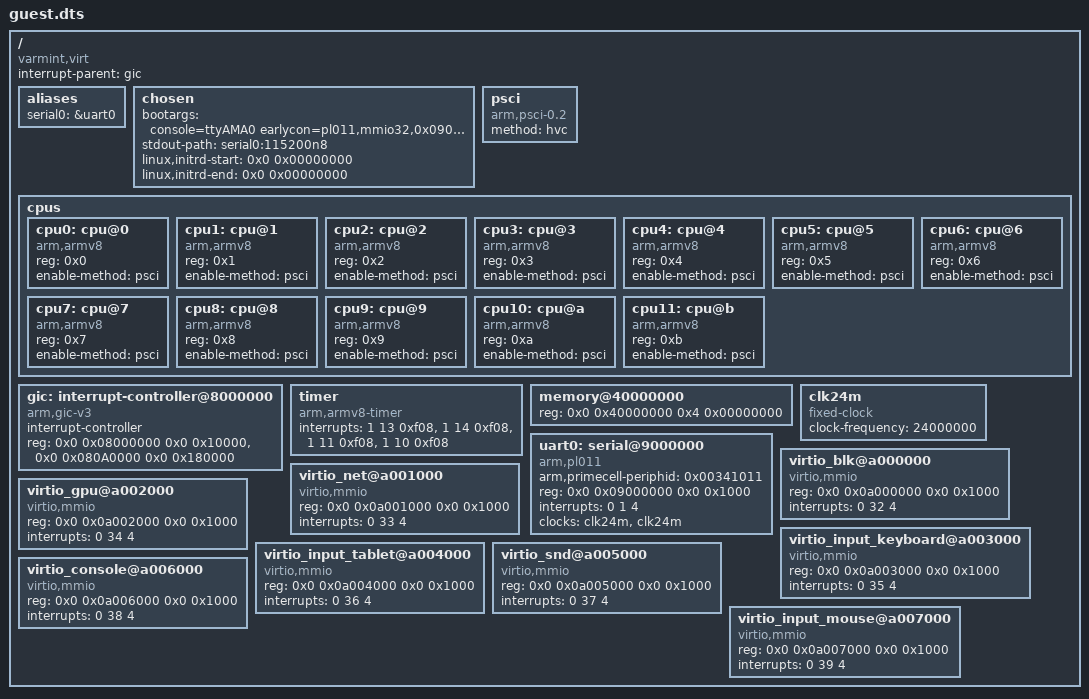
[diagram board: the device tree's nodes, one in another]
/dts-v1/;

/ {
	compatible = "varmint,virt";
	#address-cells = <2>;
	#size-cells = <2>;
	interrupt-parent = <&gic>;

	aliases {
		serial0 = &uart0;
	};

	chosen {
		bootargs = "console=ttyAMA0 earlycon=pl011,mmio32,0x09000000 root=/dev/vda3 rw";
		stdout-path = "serial0:115200n8";

		linux,initrd-start = <0x0 0x00000000>; // patched by scripts/build-dtb.sh
		linux,initrd-end = <0x0 0x00000000>; // patched by scripts/build-dtb.sh
	};

	psci {
		compatible = "arm,psci-0.2";
		method = "hvc";
	};

	cpus {
		#address-cells = <1>;
		#size-cells = <0>;

		cpu0: cpu@0 {
			device_type = "cpu";
			compatible = "arm,armv8";
			reg = <0x0>;
			enable-method = "psci";
		};

		cpu1: cpu@1 {
			device_type = "cpu";
			compatible = "arm,armv8";
			reg = <0x1>;
			enable-method = "psci";
		};

		cpu2: cpu@2 {
			device_type = "cpu";
			compatible = "arm,armv8";
			reg = <0x2>;
			enable-method = "psci";
		};

		cpu3: cpu@3 {
			device_type = "cpu";
			compatible = "arm,armv8";
			reg = <0x3>;
			enable-method = "psci";
		};

		cpu4: cpu@4 {
			device_type = "cpu";
			compatible = "arm,armv8";
			reg = <0x4>;
			enable-method = "psci";
		};

		cpu5: cpu@5 {
			device_type = "cpu";
			compatible = "arm,armv8";
			reg = <0x5>;
			enable-method = "psci";
		};

		cpu6: cpu@6 {
			device_type = "cpu";
			compatible = "arm,armv8";
			reg = <0x6>;
			enable-method = "psci";
		};

		cpu7: cpu@7 {
			device_type = "cpu";
			compatible = "arm,armv8";
			reg = <0x7>;
			enable-method = "psci";
		};

		cpu8: cpu@8 {
			device_type = "cpu";
			compatible = "arm,armv8";
			reg = <0x8>;
			enable-method = "psci";
		};

		cpu9: cpu@9 {
			device_type = "cpu";
			compatible = "arm,armv8";
			reg = <0x9>;
			enable-method = "psci";
		};

		cpu10: cpu@a {
			device_type = "cpu";
			compatible = "arm,armv8";
			reg = <0xa>;
			enable-method = "psci";
		};

		cpu11: cpu@b {
			device_type = "cpu";
			compatible = "arm,armv8";
			reg = <0xb>;
			enable-method = "psci";
		};
	};

	gic: interrupt-controller@8000000 {
		compatible = "arm,gic-v3";
		interrupt-controller;
		#interrupt-cells = <3>;

		reg = <0x0 0x08000000 0x0 0x10000>,
		<0x0 0x080A0000 0x0 0x180000>;
	};

	timer {
		compatible = "arm,armv8-timer";
		interrupts = <1 13 0xf08>,
		<1 14 0xf08>,
		<1 11 0xf08>,
		<1 10 0xf08>;
	};

	memory@40000000 {
		device_type = "memory";
		reg = <0x0 0x40000000 0x4 0x00000000>;
	};

	clk24m: clk24m {
		compatible = "fixed-clock";
		#clock-cells = <0>;
		clock-frequency = <24000000>;
	};

	uart0: serial@9000000 {
		compatible = "arm,pl011", "arm,primecell";
		arm,primecell-periphid = <0x00341011>;// dirty hack, write normal periphid later
		reg = <0x0 0x09000000 0x0 0x1000>;
		interrupts = <0 1 4>;
		clocks = <&clk24m &clk24m>;
		clock-names = "uartclk", "apb_pclk";
		status = "okay";
	};

	virtio_blk@a000000 {
		compatible = "virtio,mmio";
		reg = <0x0 0x0a000000 0x0 0x1000>;
		interrupts = <0 32 4>;
	};

	virtio_net@a001000 {
		compatible = "virtio,mmio";
		reg = <0x0 0x0a001000 0x0 0x1000>;
		interrupts = <0 33 4>;
	};

	virtio_gpu@a002000 {
		compatible = "virtio,mmio";
		reg = <0x0 0x0a002000 0x0 0x1000>;
		interrupts = <0 34 4>;
	};

	virtio_input_keyboard@a003000 {
		compatible = "virtio,mmio";
		reg = <0x0 0x0a003000 0x0 0x1000>;
		interrupts = <0 35 4>;
	};

	virtio_input_tablet@a004000 {
		compatible = "virtio,mmio";
		reg = <0x0 0x0a004000 0x0 0x1000>;
		interrupts = <0 36 4>;
	};

	virtio_snd@a005000 {
		compatible = "virtio,mmio";
		reg = <0x0 0x0a005000 0x0 0x1000>;
		interrupts = <0 37 4>;
	};

	virtio_console@a006000 {
		compatible = "virtio,mmio";
		reg = <0x0 0x0a006000 0x0 0x1000>;
		interrupts = <0 38 4>;
	};

	virtio_input_mouse@a007000 {
		compatible = "virtio,mmio";
		reg = <0x0 0x0a007000 0x0 0x1000>;
		interrupts = <0 39 4>;
	};
};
